# PAC55XX register map
Vendor: Active-Semi; Series: PAC55XX; File version: 1.0
CPU: CM4 r0p1, little endian, MPU, FPU, vendor SysTick, 3 interrupt priority bits
Registers are 32-bit, read-write, reset 0x0 unless marked. A register's access mark holds for its fields unless they carry their own. Offsets are from the block's base; [hi:lo] are bit positions; {n}, {i} and the like mark numbered series.

## USARTB
Base 0x40030000
0x00 RBR_CON — UART B Receive Buffer / SSP B Control
0x04 THR_STAT — UART B Transmit Holding / SSP B Status
0x08 DRL_DAT — UART B Divisor Latch / SSP B Data
0x0C IER_CLK — UART B Interrupt Enable / SSP B Clock Control
0x10 IIR_IMSC — UART B Interrupt Identification / SSP B Interrupt Mask Set and Clear
0x14 FCR_RIS — UART B FIFO Control / SSP B Raw Interrupt Status
0x18 LCR_MIS — UART B Line Control / SSP B Masked Interrupt Status
0x1C ICLR — SSP B Interrupt Clear
0x20 LSR — UART B Line Status
0x28 SCR_SSCR — UART B Scratch Pad / SSP B Slave Select Configuration
0x2C EFR — Enhanced Feature

## USARTC
Base 0x40040000
0x00 RBR_CON — UART C Receive Buffer / SSP C Control
0x04 THR_STAT — UART C Transmit Holding / SSP C Status
0x08 DRL_DAT — UART C Divisor Latch / SSP C Data
0x0C IER_CLK — UART C Interrupt Enable / SSP C Clock Control
0x10 IIR_IMSC — UART C Interrupt Identification / SSP C Interrupt Mask Set and Clear
0x14 FCR_RIS — UART C FIFO Control / SSP C Raw Interrupt Status
0x18 LCR_MIS — UART C Line Control / SSP C Masked Interrupt Status
0x1C ICLR — SSP C Interrupt Clear
0x20 LSR — UART C Line Status
0x28 SCR_SSCR — UART C Scratch Pad / SSP C Slave Select Configuration
0x2C EFR — Enhanced Feature

## USARTD
Base 0x40050000
0x00 RBR_CON — UART D Receive Buffer / SSP D Control
0x04 THR_STAT — UART D Transmit Holding / SSP D Status
0x08 DRL_DAT — UART D Divisor Latch / SSP D Data
0x0C IER_CLK — UART D Interrupt Enable / SSP D Clock Control
0x10 IIR_IMSC — UART D Interrupt Identification / SSP D Interrupt Mask Set and Clear
0x14 FCR_RIS — UART D FIFO Control / SSP D Raw Interrupt Status
0x18 LCR_MIS — UART D Line Control / SSP D Masked Interrupt Status
0x1C ICLR — SSP D Interrupt Clear
0x20 LSR — UART D Line Status
0x28 SCR_SSCR — UART D Scratch Pad / SSP D Slave Select Configuration
0x2C EFR — Enhanced Feature

## TimerA
Base 0x40060000
0x00 CTL — Timer A Control
0x04 INT — Timer A Interrupt Control
0x08 PRD — Timer A Period
0x0C CTR — Timer A Counter
0x10 QEPCTL — Timer A QEP Control
{0x100+8i} CCTL{i} (i=0..7) — Timer A CC Control {i}
{0x104+8i} CCTR{i} (i=0..7) — Timer A CC Counter {i}
{0x200+4i} DTGCTL{i} (i=0..3) — Timer A DTG Control {i}

## TimerB
Base 0x40070000
0x00 CTL — Timer B Control
0x04 INT — Timer B Interrupt Control
0x08 PRD — Timer B Period
0x0C CTR — Timer B Counter
0x10 QEPCTL — Timer B QEP Control
{0x100+8i} CCTL{i} (i=0..7) — Timer B CC Control {i}
{0x104+8i} CCTR{i} (i=0..7) — Timer B CC Counter {i}
{0x200+4i} DTGCTL{i} (i=0..3) — Timer B DTG Control {i}

## TimerC
Base 0x40080000
0x00 CTL — Timer C Control
0x04 INT — Timer C Interrupt Control
0x08 PRD — Timer C Period
0x0C CTR — Timer C Counter
0x10 QEPCTL — Timer C QEP Control
{0x100+8i} CCTL{i} (i=0..7) — Timer C CC Control {i}
{0x104+8i} CCTR{i} (i=0..7) — Timer C CC Counter {i}
{0x200+4i} DTGCTL{i} (i=0..3) — Timer C DTG Control {i}

## TimerD
Base 0x40090000
0x00 CTL — Timer D Control
0x04 INT — Timer D Interrupt Control
0x08 PRD — Timer D Period
0x0C CTR — Timer D Counter
0x10 QEPCTL — Timer D QEP Control
{0x100+8i} CCTL{i} (i=0..7) — Timer D CC Control {i}
{0x104+8i} CCTR{i} (i=0..7) — Timer D CC Counter {i}
{0x200+4i} DTGCTL{i} (i=0..3) — Timer D DTG Control {i}

## CAN
Base 0x400A0000
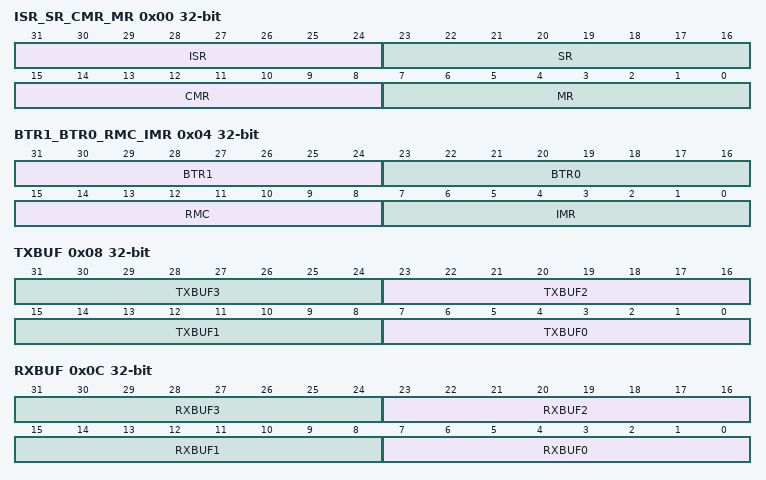
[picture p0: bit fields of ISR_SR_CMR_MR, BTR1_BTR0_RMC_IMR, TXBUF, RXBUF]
0x00 ISR_SR_CMR_MR — Combined CAN MR, CMR, SR, and ISR registers
  [31:24] ISR — CAN Interrupt Status/Acknowledge
  [23:16] SR — CAN Status
  [15:8] CMR — CAN Command
  [7:0] MR — CAN Mode
0x04 BTR1_BTR0_RMC_IMR — Combined CAN IMR, RMC, BTR0, and BTR1 registers
  [31:24] BTR1 — CAN Bus Timing Register 1
  [23:16] BTR0 — CAN Bus Timing Register 0
  [15:8] RMC — CAN Receive Message Counter
  [7:0] IMR — CAN Interrupt Mask
0x08 TXBUF — Combined CAN Transmit Buffer registers
  [8n+7:8n] TXBUF{n} (n=0..3) — CAN Transmit Buffer {n}
0x0C RXBUF — Combined CAN Receive Buffer registers
  [8n+7:8n] RXBUF{n} (n=0..3) — CAN Receive Buffer {n}
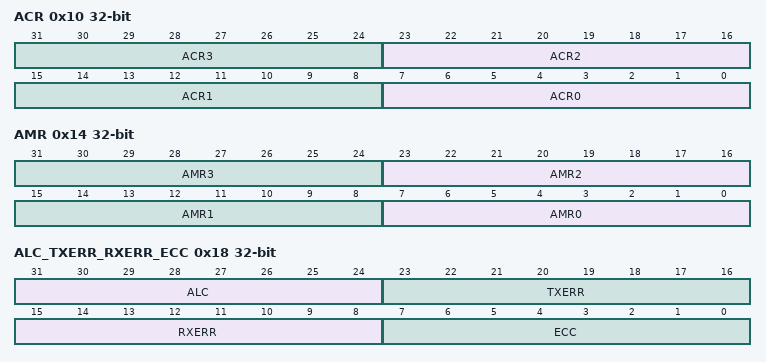
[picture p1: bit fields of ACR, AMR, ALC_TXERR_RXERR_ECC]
0x10 ACR — Combined CAN Acceptance Code registers
  [8n+7:8n] ACR{n} (n=0..3) — CAN Acceptance Code {n}
0x14 AMR — Combined CAN Acceptance Mask registers
  [8n+7:8n] AMR{n} (n=0..3) — CAN Acceptance Mask {n}
0x18 ALC_TXERR_RXERR_ECC — Combined CAN ECC, RXERR, TXERR, and ALC registers
  [31:24] ALC — CAN Arbitration Lost Code Capture
  [23:16] TXERR — CAN TX Error Counter
  [15:8] RXERR — CAN RX Error Counter
  [7:0] ECC — CAN Error Code Capture
